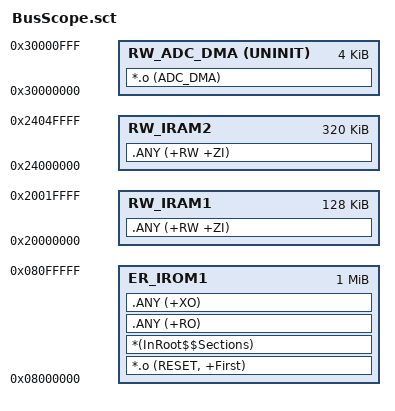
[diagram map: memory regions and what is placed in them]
; STM32H723: DMA1 cannot access DTCM. Keep the ADC circular buffer in SRAM1.
; BusScope_AcquisitionInit enables SRAM1 and initializes ADC_DMA before DMA.
LR_IROM1 0x08000000 0x00100000 {
  ER_IROM1 0x08000000 0x00100000 {
    *.o (RESET, +First)
    *(InRoot$$Sections)
    .ANY (+RO)
    .ANY (+XO)
  }
  RW_ADC_DMA 0x30000000 UNINIT 0x00001000 {
    *.o (ADC_DMA)
  }
  RW_IRAM1 0x20000000 0x00020000 {
    .ANY (+RW +ZI)
  }
  RW_IRAM2 0x24000000 0x00050000 {
    .ANY (+RW +ZI)
  }
}
